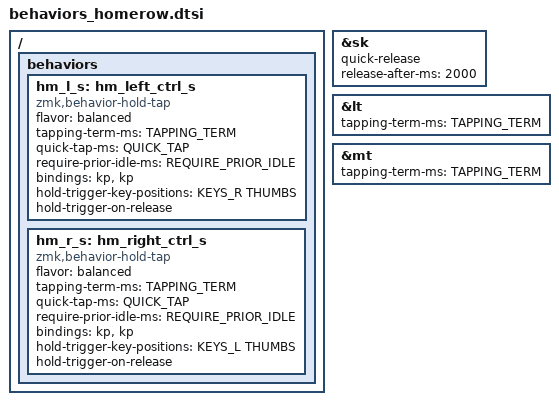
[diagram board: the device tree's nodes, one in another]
// Home row mods behaviors for Kinesis Advantage 2 (Helios)

#include <behaviors.dtsi>
#include <dt-bindings/zmk/keys.h>
#include "keypos_helios.h"

// Configuration for home row mods
#define TAPPING_TERM 200
#define QUICK_TAP 175
#define REQUIRE_PRIOR_IDLE 150

/ {
    behaviors {
        // Left-hand home row mods
        hm_l_s: hm_left_ctrl_s {
            compatible = "zmk,behavior-hold-tap";
            #binding-cells = <2>;
            flavor = "balanced";
            tapping-term-ms = <TAPPING_TERM>;
            quick-tap-ms = <QUICK_TAP>;
            require-prior-idle-ms = <REQUIRE_PRIOR_IDLE>;
            bindings = <&kp>, <&kp>;
            hold-trigger-key-positions = <KEYS_R THUMBS>;
            hold-trigger-on-release;
        };

        // Right-hand home row mods
        hm_r_s: hm_right_ctrl_s {
            compatible = "zmk,behavior-hold-tap";
            #binding-cells = <2>;
            flavor = "balanced";
            tapping-term-ms = <TAPPING_TERM>;
            quick-tap-ms = <QUICK_TAP>;
            require-prior-idle-ms = <REQUIRE_PRIOR_IDLE>;
            bindings = <&kp>, <&kp>;
            hold-trigger-key-positions = <KEYS_L THUMBS>;
            hold-trigger-on-release;
        };
    };
};

// For increased responsiveness in certain key combinations
&sk {
    quick-release;
    release-after-ms = <2000>;
};

&lt {
    tapping-term-ms = <TAPPING_TERM>;
};

&mt {
    tapping-term-ms = <TAPPING_TERM>;
}; 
